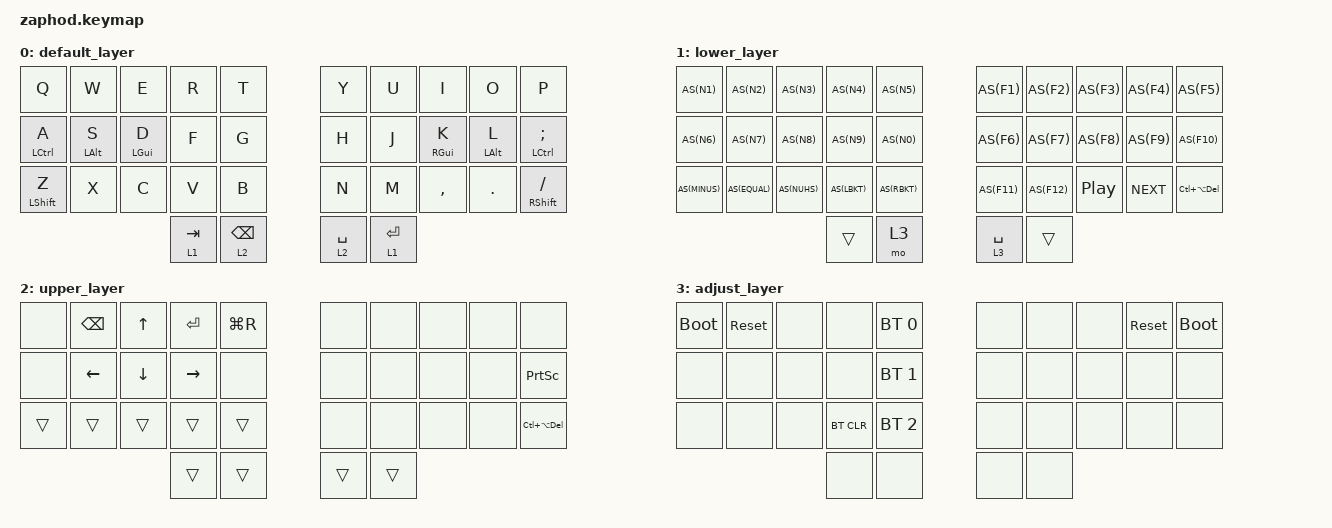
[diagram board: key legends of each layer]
/*
 * Copyright (c) 2021 Pete Johanson
 *
 * SPDX-License-Identifier: MIT
 */

#include <behaviors.dtsi>
#include <dt-bindings/zmk/keys.h>
#include <dt-bindings/zmk/bt.h>
#include <dt-bindings/zmk/outputs.h>

#define AS(keycode) &as LS(keycode) keycode     // Autoshift Macro

&lt {
    tapping-term-ms = <170>;
    quick-tap-ms = <150>;
    require-prior-idle-ms = <125>;
    global-quick-tap;
};

/ {
    combos {
        compatible = "zmk,combos";
        combo_lsbrc {
            layers = <0>;
            timeout-ms = <15>;
            key-positions = <3 4>;
            bindings = <&kp LBKT>;
        };
        combo_rsbrc {
            layers = <0>;
            timeout-ms = <15>;
            key-positions = <5 6>;
            bindings = <&kp RBKT>;
        };
        combo_lbrc {
            layers = <0>;
            timeout-ms = <15>;
            key-positions = <13 14>;
            bindings = <&kp LS(N9)>;
        };
        combo_rbrc {
            layers = <0>;
            timeout-ms = <15>;
            key-positions = <15 16>;
            bindings = <&kp LS(N0)>;
        };
        combo_lcbrc {
            layers = <0>;
            timeout-ms = <15>;
            key-positions = <23 24>;
            bindings = <&kp LS(LBKT)>;
        };
        combo_rcbrc {
            layers = <0>;
            timeout-ms = <15>;
            key-positions = <25 26>;
            bindings = <&kp LS(RBKT)>;
        };
        combo_esc {
            layers = <0>;
            timeout-ms = <15>;
            key-positions = <0 1>;
            bindings = <&kp ESC>;
        };
        combo_del {
            layers = <0>;
            timeout-ms = <15>;
            key-positions = <8 9>;
            bindings = <&kp DEL>;
        };
        combo_grv {
            layers = <0>;
            timeout-ms = <15>;
            key-positions = <1 2>;
            bindings = <&kp GRAVE>;
        };
        combo_quot {
            layers = <0>;
            timeout-ms = <15>;
            key-positions = <17 18>;
            bindings = <AS(SQT)>;
        };
        combo_prt {
            layers = <0>;
            timeout-ms = <15>;
            key-positions = <18 19>;
            bindings = <&kp PSCRN>;
        };
        combo_nuhs {
            layers = <0>;
            timeout-ms = <15>;
            key-positions = <26 27>;
            bindings = <&kp NUHS>;
        };
        combo_nubs {
            layers = <0>;
            timeout-ms = <15>;
            key-positions = <11 12>;
            bindings = <&kp NUBS>;
        };
        combo_dash {
            layers = <0>;
            timeout-ms = <15>;
            key-positions = <21 22>;
            bindings = <&kp MINUS>;
        };
        combo_equals {
            layers = <0>;
            timeout-ms = <15>;
            key-positions = <22 23>;
            bindings = <&kp EQUAL>;
        };
        combo_question {
            layers = <0>;
            timeout-ms = <15>;
            key-positions = <28 29>;
            bindings = <&kp LS(FSLH)>;
        };
    };
    behaviors {
        ht: hold_tap {
            label = "hold_tap";
            compatible = "zmk,behavior-hold-tap";
            #binding-cells = <2>;
            flavor = "tap-preferred";
            tapping-term-ms = <170>;
            quick-tap-ms = <150>;
            global-quick-tap;
            require-prior-idle-ms = <125>;
            bindings = <&kp>, <&kp>;
        };
        as: auto_shift {
            compatible = "zmk,behavior-hold-tap";
            label = "AUTO_SHIFT";
            #binding-cells = <2>;
            tapping_term_ms = <160>;
            quick_tap_ms = <0>;
            flavor = "tap-preferred";
            bindings = <&kp>, <&kp>;
        };
    };

    keymap {
        compatible = "zmk,keymap";
        default_layer {
            bindings = <
                    &kp Q           &kp W           &kp E           &kp R           &kp T           &kp Y           &kp U          &kp I           &kp O           &kp P
                    &ht LCTRL A     &ht LALT S      &ht LGUI D      &kp F           &kp G           &kp H           &kp J          &ht RGUI K      &ht LALT L       &ht LCTRL SEMI  
                    &ht LSHIFT Z    &kp X           &kp C           &kp V           &kp B           &kp N           &kp M          &kp COMMA       &kp DOT          &ht RSHIFT FSLH
                                                            &lt 1 TAB       &lt 2 BSPC      &lt 2 SPACE     &lt 1 ENTER
            >;
        };

        lower_layer {
            bindings = <
                    AS(N1)          AS(N2)          AS(N3)          AS(N4)          AS(N5)           AS(F1)          AS(F2)         AS(F3)          AS(F4)         AS(F5)
                    AS(N6)          AS(N7)          AS(N8)          AS(N9)          AS(N0)           AS(F6)          AS(F7)         AS(F8)          AS(F9)          AS(F10)  
                    AS(MINUS)       AS(EQUAL)       AS(NUHS)        AS(LBKT)        AS(RBKT)         AS(F11)         AS(F12)        &kp C_PP        &kp C_NEXT      &kp LC(LA(DEL))
                                                            &trans          &mo 3            &lt 3 SPACE     &trans
            >;
        };

        upper_layer {
            bindings = <
                    &none           &kp BSPC        &kp UP          &kp ENTER       &kp LG(R)       &none           &none           &none           &none           &none
                    &none           &kp LEFT        &kp DOWN        &kp RIGHT       &none           &none           &none           &none           &none           &kp PSCRN 
                    &trans          &trans          &trans          &trans          &trans          &none           &none           &none           &none           &kp LC(LA(DEL))
                                                            &trans          &trans          &trans          &trans
            >;
        };

        adjust_layer {
            bindings = <
                    &bootloader     &sys_reset      &none           &none           &bt BT_SEL 0    &none           &none           &none           &sys_reset      &bootloader
                    &none           &none           &none           &none           &bt BT_SEL 1    &none           &none           &none           &none           &none 
                    &none           &none           &none           &bt BT_CLR      &bt BT_SEL 2    &none           &none           &none           &none           &none
                                                            &none           &none           &none           &none
            >;
        };
    };
};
